# i2s_reva_me17 register map
Registers are 32-bit, read-write, no defined reset value unless marked. A register's access mark holds for its fields unless they carry their own. Offsets are from the block's base; lines under a group give offsets from that group; [hi:lo] are bit positions; {n}, {i} and the like mark numbered series; 'fields as' and 'values as' point back to an identical list; <NAME> marks a mode.

## Memory map
0x40060000 I2S size 0x1000 — Inter-IC Sound Interface.

## Interrupts
99 I2S — I2S IRQ

## I2S — Inter-IC Sound Interface.
Base 0x40060000
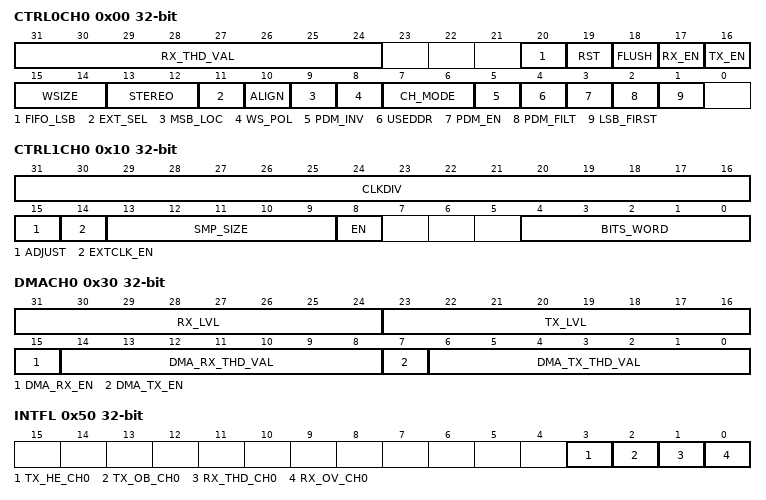
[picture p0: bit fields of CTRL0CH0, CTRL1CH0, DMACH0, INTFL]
0x00 CTRL0CH0 access per field — Global mode channel.
  [31:24] RX_THD_VAL rw — depth of receive FIFO for threshold interrupt generation.
  [20] FIFO_LSB rw — Bit Field Control.
  [19] RST rw — Write 1 to reset channel.
  [18] FLUSH rw — Flushes the TX/RX FIFO buffer.
  [17] RX_EN rw — RX channel enable.
  [16] TX_EN rw — TX channel enable.
  [15:14] WSIZE rw — Data size when write to FIFO.
  [13:12] STEREO ro — Stereo mode of I2S.
  [11] EXT_SEL rw — External SCK/WS selection.
  [10] ALIGN ro — Align to MSB or LSB.
  [9] MSB_LOC ro — MSB location.
  [8] WS_POL rw — WS polarity select.
  [7:6] CH_MODE rw — SCK Select.
  [5] PDM_INV rw — Invert PDM.
  [4] USEDDR rw — DDR.
  [3] PDM_EN rw — PDM Enable.
  [2] PDM_FILT rw — PDM Filter.
  [1] LSB_FIRST rw — LSB Transmit Receive First.
0x10 CTRL1CH0 — Local channel Setup.
  [31:16] CLKDIV — I2S clock frequency divisor.
  [15] ADJUST — LSB/MSB Justify.
  [14] EXTCLK_EN — Selects the clock source for master mode operations in the ME17B.
    0=erfo (Use ERFO.); 1=ext (Use External Clock.)
  [13:9] SMP_SIZE — I2S sample size length.
  [8] EN — I2S clock enable.
  [4:0] BITS_WORD — I2S word length.
0x20 FILTCH0 access not given — Filter.
0x30 DMACH0 — DMA Control.
  [31:24] RX_LVL — Number of data word in the RX FIFO.
  [23:16] TX_LVL — Number of data word in the TX FIFO.
  [15] DMA_RX_EN — RX DMA channel enable.
  [14:8] DMA_RX_THD_VAL — RX FIFO Level DMA Trigger.
  [7] DMA_TX_EN — TX DMA channel enable.
  [6:0] DMA_TX_THD_VAL — TX FIFO Level DMA Trigger.
0x40 FIFOCH0 — I2S Fifo.
  [31:0] DATA — Load/unload location for TX and RX FIFO buffers.
0x50 INTFL — ISR Status.
  [3] TX_HE_CH0 — Status for interrupt when TX FIFO is half empty.
  [2] TX_OB_CH0 — Status for interrupt when TX FIFO has only one byte remaining.
  [1] RX_THD_CH0 — Status for interrupt when RX FIFO reaches the number of bytes configured by the RXTHD field.
  [0] RX_OV_CH0 — Status for RX FIFO Overrun interrupt.
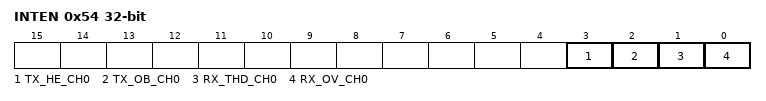
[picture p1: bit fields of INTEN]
0x54 INTEN — Interrupt Enable.
  [3] TX_HE_CH0 — Enable for interrupt when TX FIFO is half empty.
  [2] TX_OB_CH0 — Enable for interrupt when TX FIFO has only one byte remaining.
  [1] RX_THD_CH0 — Enable for interrupt when RX FIFO reaches the number of bytes configured by the RXTHD field.
  [0] RX_OV_CH0 — Enable for RX FIFO Overrun interrupt.
0x58 EXTSETUP — Ext Control.
  [4:0] EXT_BITS_WORD — Word Length for ch_mode.
0x5C WKEN access not given — Wakeup Enable.
0x60 WKFL access not given — Wakeup Flags.
